# DSPIC33CK256MP506 register map
Vendor: Microchip
Architecture 33xxxx. Special function registers and configuration words.
Registers are 24-bit, read-write, reset 0xFFFFFF unless marked. A register's access mark holds for its fields unless they carry their own. Addresses are absolute, and some are shared; only a register's first bit layout is shown; lines under a group give offsets from that group; [hi:lo] are bit positions; {n}, {i} and the like mark numbered series; 'fields as' and 'values as' point back to an identical list; <NAME> marks a mode.

## Further device data
pins=1: MCLR; 2: PGD2/OA2IN-/AN8/RP35/RB3; 3: PGC2/OA2IN+/RP36/RB4; 4: PGD3/RP37/SDA2/PMA14/PMCS1/PSCS/RB5; 5: PGC3/RP38/SCL2/RB6; 6: PGD1/AN10/RP40/SCL1/RB8; 7: PGC1/AN11/RP41/SDA1/RB9

## TIMER1
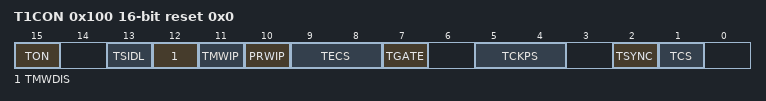
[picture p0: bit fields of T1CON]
0x100 T1CON 16-bit reset 0x0
  [15] TON, [13] TSIDL, [12] TMWDIS, [11] TMWIP, [10] PRWIP, [9:8] TECS, [7] TGATE, [5:4] TCKPS, [2] TSYNC, [1] TCS
0x104 TMR1 16-bit reset 0x0
  [15:0] TMR
0x108 PR1 16-bit reset 0xFFFF
  [15:0] PR

## WACG
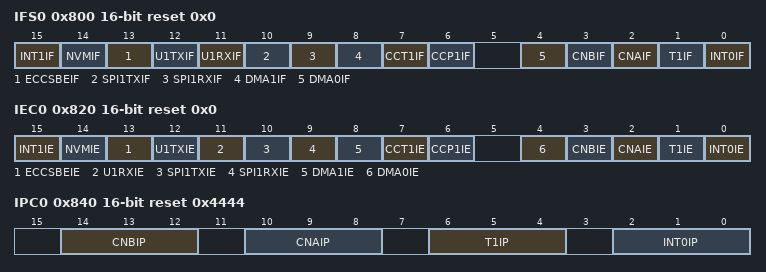
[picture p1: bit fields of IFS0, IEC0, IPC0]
0x800 IFS0 16-bit reset 0x0
  [15] INT1IF, [14] NVMIF, [13] ECCSBEIF, [12] U1TXIF, [11] U1RXIF, [10] SPI1TXIF, [9] SPI1RXIF, [8] DMA1IF, [7] CCT1IF, [6] CCP1IF, [4] DMA0IF, [3] CNBIF, [2] CNAIF, [1] T1IF, [0] INT0IF
0x820 IEC0 16-bit reset 0x0
  [15] INT1IE, [14] NVMIE, [13] ECCSBEIE, [12] U1TXIE, [11] U1RXIE, [10] SPI1TXIE, [9] SPI1RXIE, [8] DMA1IE, [7] CCT1IE, [6] CCP1IE, [4] DMA0IE, [3] CNBIE, [2] CNAIE, [1] T1IE, [0] INT0IE
0x840 IPC0 16-bit reset 0x4444
  [14:12] CNBIP, [10:8] CNAIP, [6:4] T1IP, [2:0] INT0IP

## GPIOA
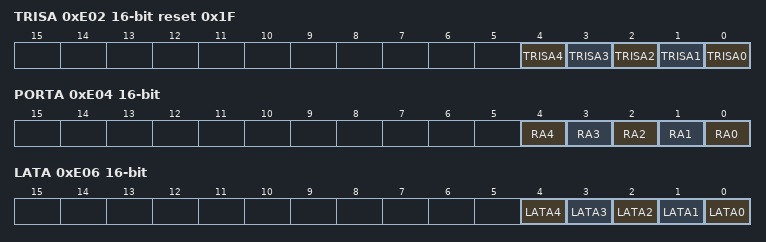
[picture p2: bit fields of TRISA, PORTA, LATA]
0xE02 TRISA 16-bit reset 0x1F
  [n] TRISA{n} (n=0..4)
0xE04 PORTA 16-bit reset not defined — (power-on value -----------xxxxx)
  [n] RA{n} (n=0..4)
0xE06 LATA 16-bit reset not defined — (power-on value -----------xxxxx)
  [n] LATA{n} (n=0..4)

## rst_integration
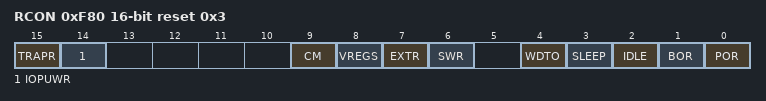
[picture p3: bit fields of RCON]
0xF80 RCON 16-bit reset 0x3
  [15] TRAPR, [14] IOPUWR, [9] CM, [8] VREGS, [7] EXTR, [6] SWR, [4] WDTO, [3] SLEEP, [2] IDLE, [1] BOR, [0] POR

## clk_sib
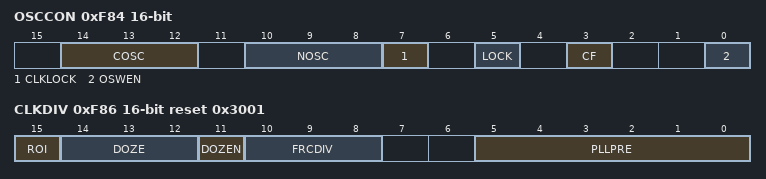
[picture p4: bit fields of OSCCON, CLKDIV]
0xF84 OSCCON 16-bit reset not defined — (power-on value -000-yyy0-0-0--0)
  [14:12] COSC ro
  [10:8] NOSC
  [7] CLKLOCK
  [5] LOCK ro
  [3] CF — (can only be cleared)
  [0] OSWEN
0xF86 CLKDIV 16-bit reset 0x3001
  [15] ROI, [14:12] DOZE, [11] DOZEN, [10:8] FRCDIV, [5:0] PLLPRE
